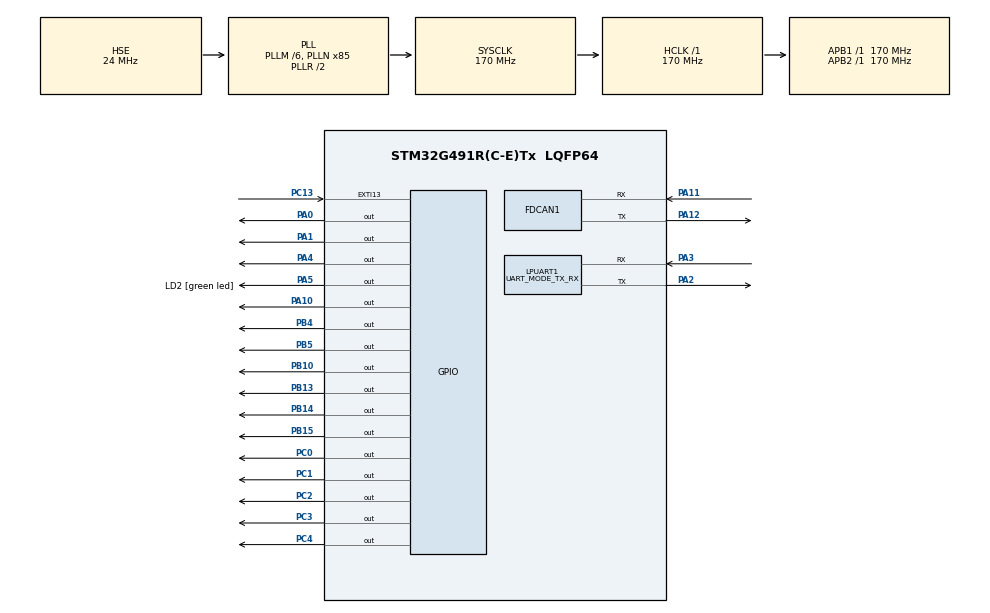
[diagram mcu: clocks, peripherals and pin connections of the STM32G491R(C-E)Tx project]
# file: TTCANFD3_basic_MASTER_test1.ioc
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Dma.LPUART1_TX.0.Direction=DMA_MEMORY_TO_PERIPH
Dma.LPUART1_TX.0.EventEnable=DISABLE
Dma.LPUART1_TX.0.Instance=DMA1_Channel1
Dma.LPUART1_TX.0.MemDataAlignment=DMA_MDATAALIGN_BYTE
Dma.LPUART1_TX.0.MemInc=DMA_MINC_ENABLE
Dma.LPUART1_TX.0.Mode=DMA_NORMAL
Dma.LPUART1_TX.0.PeriphDataAlignment=DMA_PDATAALIGN_BYTE
Dma.LPUART1_TX.0.PeriphInc=DMA_PINC_DISABLE
Dma.LPUART1_TX.0.Polarity=HAL_DMAMUX_REQ_GEN_RISING
Dma.LPUART1_TX.0.Priority=DMA_PRIORITY_VERY_HIGH
Dma.LPUART1_TX.0.RequestNumber=1
Dma.LPUART1_TX.0.SignalID=NONE
Dma.LPUART1_TX.0.SyncEnable=DISABLE
Dma.LPUART1_TX.0.SyncPolarity=HAL_DMAMUX_SYNC_NO_EVENT
Dma.LPUART1_TX.0.SyncRequestNumber=1
Dma.LPUART1_TX.0.SyncSignalID=NONE
Dma.Request0=LPUART1_TX
FDCAN1.AutoRetransmission=DISABLE
FDCAN1.CalculateBaudRateNominal=500000
FDCAN1.CalculateTimeBitNominal=2000
FDCAN1.CalculateTimeQuantumNominal=100.0
FDCAN1.DataPrescaler=5
FDCAN1.DataSyncJumpWidth=8
FDCAN1.DataTimeSeg1=12
FDCAN1.DataTimeSeg2=4
FDCAN1.FrameFormat=FDCAN_FRAME_FD_BRS
FDCAN1.NominalPrescaler=17
FDCAN1.NominalSyncJumpWidth=8
FDCAN1.NominalTimeSeg1=15
FDCAN1.NominalTimeSeg2=4
FDCAN1.ProtocolException=ENABLE
FDCAN1.StdFiltersNbr=1
FDCAN1.TransmitPause=ENABLE
LPUART1.Mode=UART_MODE_TX_RX
Mcu.Family=STM32G4
Mcu.Name=STM32G491R(C-E)Tx
Mcu.Package=LQFP64
NVIC.DMA1_Channel1_IRQn=true\:0\:0\:false\:false\:true\:false\:true\:true
NVIC.EXTI15_10_IRQn=true\:0\:1\:false\:false\:true\:true\:true\:true
NVIC.FDCAN1_IT0_IRQn=true\:0\:1\:false\:false\:true\:true\:true\:true
NVIC.FDCAN1_IT1_IRQn=true\:0\:1\:false\:false\:true\:true\:true\:true
NVIC.LPUART1_IRQn=true\:0\:0\:false\:false\:true\:true\:true\:true
NVIC.PriorityGroup=NVIC_PRIORITYGROUP_3
NVIC.TIM1_BRK_TIM15_IRQn=true\:1\:0\:true\:false\:true\:true\:true\:true
NVIC.TIM1_CC_IRQn=true\:0\:1\:true\:false\:true\:true\:true\:true
NVIC.TIM1_TRG_COM_TIM17_IRQn=true\:1\:0\:true\:false\:true\:true\:true\:true
NVIC.TIM1_UP_TIM16_IRQn=true\:1\:0\:true\:false\:true\:true\:true\:true
NVIC.TIM3_IRQn=true\:0\:1\:true\:false\:true\:true\:true\:true
NVIC.TIM4_IRQn=true\:0\:1\:true\:false\:true\:true\:true\:true
PA0.Signal=GPIO_Output
PA1.Signal=GPIO_Output
PA10.Signal=GPIO_Output
PA11.GPIO_Speed=GPIO_SPEED_FREQ_VERY_HIGH
PA11.Mode=FDCAN_Activate
PA11.Signal=FDCAN1_RX
PA12.GPIO_Speed=GPIO_SPEED_FREQ_VERY_HIGH
PA12.Mode=FDCAN_Activate
PA12.Signal=FDCAN1_TX
PA13.GPIO_Label=T_SWDIO
PA13.Mode=Trace_Asynchronous_SW
PA13.Signal=SYS_JTMS-SWDIO
PA14.GPIO_Label=T_SWCLK
PA14.Mode=Trace_Asynchronous_SW
PA14.Signal=SYS_JTCK-SWCLK
PA2.GPIO_Mode=GPIO_MODE_AF_PP
PA2.GPIO_PuPd=GPIO_NOPULL
PA2.GPIO_Speed=GPIO_SPEED_FREQ_VERY_HIGH
PA2.Mode=Asynchronous
PA2.Signal=LPUART1_TX
PA3.GPIO_Mode=GPIO_MODE_AF_PP
PA3.GPIO_PuPd=GPIO_NOPULL
PA3.GPIO_Speed=GPIO_SPEED_FREQ_VERY_HIGH
PA3.Mode=Asynchronous
PA3.Signal=LPUART1_RX
PA4.Signal=GPIO_Output
PA5.GPIO_Label=LD2 [green led]
PA5.Signal=GPIO_Output
PB10.Signal=GPIO_Output
PB13.Signal=GPIO_Output
PB14.Signal=GPIO_Output
PB15.Signal=GPIO_Output
PB3.GPIO_Label=T_SWO
PB3.Mode=Trace_Asynchronous_SW
PB3.Signal=SYS_JTDO-SWO
PB4.Signal=GPIO_Output
PB5.Signal=GPIO_Output
PC0.Signal=GPIO_Output
PC1.Signal=GPIO_Output
PC13.Signal=GPXTI13
PC14-OSC32_IN.GPIO_Label=RCC_OSC32_IN
PC14-OSC32_IN.Mode=LSE-External-Oscillator
PC14-OSC32_IN.Signal=RCC_OSC32_IN
PC15-OSC32_OUT.GPIO_Label=RCC_OSC32_OUT
PC15-OSC32_OUT.Mode=LSE-External-Oscillator
PC15-OSC32_OUT.Signal=RCC_OSC32_OUT
PC2.Signal=GPIO_Output
PC3.Signal=GPIO_Output
PC4.Signal=GPIO_Output
PF0-OSC_IN.GPIO_Label=RCC_OSC_IN
PF0-OSC_IN.Mode=HSE-External-Oscillator
PF0-OSC_IN.Signal=RCC_OSC_IN
PF1-OSC_OUT.GPIO_Label=RCC_OSC_OUT
PF1-OSC_OUT.Mode=HSE-External-Oscillator
PF1-OSC_OUT.Signal=RCC_OSC_OUT
ProjectManager.HeapSize=0x600
ProjectManager.StackSize=0x600
ProjectManager.TargetToolchain=STM32CubeIDE
RCC.ADC12Freq_Value=170000000
RCC.ADC345Freq_Value=170000000
RCC.AHBFreq_Value=170000000
RCC.APB1Freq_Value=170000000
RCC.APB1TimFreq_Value=170000000
RCC.APB2Freq_Value=170000000
RCC.APB2TimFreq_Value=170000000
RCC.CortexFreq_Value=170000000
RCC.EXTERNAL_CLOCK_VALUE=12288000
RCC.HCLKFreq_Value=170000000
RCC.HSE_VALUE=24000000
RCC.HSI48_VALUE=48000000
RCC.HSI_VALUE=16000000
RCC.LPUART1CLockSelection=RCC_LPUART1CLKSOURCE_HSI
RCC.PLLM=RCC_PLLM_DIV6
RCC.PLLN=85
RCC.PLLSourceVirtual=RCC_PLLSOURCE_HSE
RCC.RTCClockSelection=RCC_RTCCLKSOURCE_LSE
RCC.SYSCLKFreq_VALUE=170000000
RCC.SYSCLKSource=RCC_SYSCLKSOURCE_PLLCLK
RCC.USBFreq_Value=48000000
RCC.VCOOutputFreq_Value=340000000
TIM1.AutoReloadPreload=TIM_AUTORELOAD_PRELOAD_DISABLE
TIM1.Channel-Output\ Compare1\ No\ Output=TIM_CHANNEL_1
TIM1.Channel-Output\ Compare2\ No\ Output=TIM_CHANNEL_2
TIM1.Channel-Output\ Compare3\ No\ Output=TIM_CHANNEL_3
TIM1.Channel-Output\ Compare4\ No\ Output=TIM_CHANNEL_4
TIM1.ClockDivision=TIM_CLOCKDIVISION_DIV1
TIM1.OC1Preload=DISABLE
TIM1.OC2Preload=DISABLE
TIM1.OC3Preload-Output\ Compare3\ No\ Output=DISABLE
TIM1.OC4Preload=DISABLE
TIM1.OCMode_1=TIM_OCMODE_TOGGLE
TIM1.OCMode_2=TIM_OCMODE_TOGGLE
TIM1.OCMode_3=TIM_OCMODE_TOGGLE
TIM1.OCMode_4=TIM_OCMODE_TOGGLE
TIM1.PeriodNoDither=9999
TIM1.Prescaler=170-1
TIM2.Prescaler=170-1
TIM3.Prescaler=170-1
TIM4.PeriodNoDither=150-1
TIM4.Prescaler=170-1
VP_SYS_VS_DBSignals.Mode=DisableDeadBatterySignals
VP_TIM1_VS_ClockSourceINT.Mode=Internal
VP_TIM1_VS_no_output1.Mode=Output Compare1 No Output
VP_TIM1_VS_no_output2.Mode=Output Compare2 No Output
VP_TIM1_VS_no_output3.Mode=Output Compare3 No Output
VP_TIM1_VS_no_output4.Mode=Output Compare4 No Output
VP_TIM2_VS_ClockSourceINT.Mode=Internal
VP_TIM3_VS_ClockSourceINT.Mode=Internal
VP_TIM4_VS_ClockSourceINT.Mode=Internal
board=NUCLEO-G491RE

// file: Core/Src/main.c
/* USER CODE BEGIN Header */
/**
  ******************************************************************************
  * @file           : main.c
  * @brief          : Main program body
  ******************************************************************************
  * @attention
  *
  * Copyright (c) 2026 STMicroelectronics.
  * All rights reserved.
  *
  * This software is licensed under terms that can be found in the LICENSE file
  * in the root directory of this software component.
  * If no LICENSE file comes with this software, it is provided AS-IS.
  *
  ******************************************************************************
  */
/* USER CODE END Header */
#include "main.h"

/* USER CODE BEGIN Includes */
#include "Main_Funcs.h"
/* USER CODE END Includes */

FDCAN_HandleTypeDef hfdcan1;

UART_HandleTypeDef hlpuart1;
DMA_HandleTypeDef hdma_lpuart1_tx;

TIM_HandleTypeDef htim1;
TIM_HandleTypeDef htim2;
TIM_HandleTypeDef htim3;
TIM_HandleTypeDef htim4;

void SystemClock_Config(void);
static void MX_GPIO_Init(void);
static void MX_DMA_Init(void);
static void MX_FDCAN1_Init(void);
static void MX_TIM1_Init(void);
static void MX_TIM2_Init(void);
static void MX_LPUART1_UART_Init(void);
static void MX_TIM3_Init(void);
static void MX_TIM4_Init(void);

int main(void)
{

  /* MCU Configuration--------------------------------------------------------*/

  /* Reset of all peripherals, Initializes the Flash interface and the Systick. */
  HAL_Init();

  /* Configure the system clock */
  SystemClock_Config();

  /* Initialize all configured peripherals */
  MX_GPIO_Init();
  MX_DMA_Init();
  MX_FDCAN1_Init();
  MX_TIM1_Init();
  MX_TIM2_Init();
  MX_LPUART1_UART_Init();
  MX_TIM3_Init();
  MX_TIM4_Init();
  /* USER CODE BEGIN 2 */
  MainInit();
  /* USER CODE END 2 */

  /* Infinite loop */
  /* USER CODE BEGIN WHILE */
  while (1)
  {
	 MainLoop();

    /* USER CODE END WHILE */

  }
}

void SystemClock_Config(void)
{
  RCC_OscInitTypeDef RCC_OscInitStruct = {0};
  RCC_ClkInitTypeDef RCC_ClkInitStruct = {0};

  /** Configure the main internal regulator output voltage
  */
  HAL_PWREx_ControlVoltageScaling(PWR_REGULATOR_VOLTAGE_SCALE1_BOOST);

  /** Initializes the RCC Oscillators according to the specified parameters
  * in the RCC_OscInitTypeDef structure.
  */
  RCC_OscInitStruct.OscillatorType = RCC_OSCILLATORTYPE_HSI|RCC_OSCILLATORTYPE_HSE;
  RCC_OscInitStruct.HSEState = RCC_HSE_ON;
  RCC_OscInitStruct.HSIState = RCC_HSI_ON;
  RCC_OscInitStruct.HSICalibrationValue = RCC_HSICALIBRATION_DEFAULT;
  RCC_OscInitStruct.PLL.PLLState = RCC_PLL_ON;
  RCC_OscInitStruct.PLL.PLLSource = RCC_PLLSOURCE_HSE;
  RCC_OscInitStruct.PLL.PLLM = RCC_PLLM_DIV6;
  RCC_OscInitStruct.PLL.PLLN = 85;
  RCC_OscInitStruct.PLL.PLLP = RCC_PLLP_DIV2;
  RCC_OscInitStruct.PLL.PLLQ = RCC_PLLQ_DIV2;
  RCC_OscInitStruct.PLL.PLLR = RCC_PLLR_DIV2;
  if (HAL_RCC_OscConfig(&RCC_OscInitStruct) != HAL_OK)
  {
    Error_Handler();
  }

  /** Initializes the CPU, AHB and APB buses clocks
  */
  RCC_ClkInitStruct.ClockType = RCC_CLOCKTYPE_HCLK|RCC_CLOCKTYPE_SYSCLK
                              |RCC_CLOCKTYPE_PCLK1|RCC_CLOCKTYPE_PCLK2;
  RCC_ClkInitStruct.SYSCLKSource = RCC_SYSCLKSOURCE_PLLCLK;
  RCC_ClkInitStruct.AHBCLKDivider = RCC_SYSCLK_DIV1;
  RCC_ClkInitStruct.APB1CLKDivider = RCC_HCLK_DIV1;
  RCC_ClkInitStruct.APB2CLKDivider = RCC_HCLK_DIV1;

  if (HAL_RCC_ClockConfig(&RCC_ClkInitStruct, FLASH_LATENCY_4) != HAL_OK)
  {
    Error_Handler();
  }
}

static void MX_FDCAN1_Init(void)
{

  hfdcan1.Instance = FDCAN1;
  hfdcan1.Init.ClockDivider = FDCAN_CLOCK_DIV1;
  hfdcan1.Init.FrameFormat = FDCAN_FRAME_FD_BRS;
  hfdcan1.Init.Mode = FDCAN_MODE_NORMAL;
  hfdcan1.Init.AutoRetransmission = DISABLE;
  hfdcan1.Init.TransmitPause = ENABLE;
  hfdcan1.Init.ProtocolException = ENABLE;
  hfdcan1.Init.NominalPrescaler = 17;
  hfdcan1.Init.NominalSyncJumpWidth = 8;
  hfdcan1.Init.NominalTimeSeg1 = 15;
  hfdcan1.Init.NominalTimeSeg2 = 4;
  hfdcan1.Init.DataPrescaler = 5;
  hfdcan1.Init.DataSyncJumpWidth = 8;
  hfdcan1.Init.DataTimeSeg1 = 12;
  hfdcan1.Init.DataTimeSeg2 = 4;
  hfdcan1.Init.StdFiltersNbr = 1;
  hfdcan1.Init.ExtFiltersNbr = 0;
  hfdcan1.Init.TxFifoQueueMode = FDCAN_TX_FIFO_OPERATION;
  if (HAL_FDCAN_Init(&hfdcan1) != HAL_OK)
  {
    Error_Handler();
  }
  /* USER CODE BEGIN FDCAN1_Init 2 */
  FDCAN_FilterTypeDef canfdfilter;

  canfdfilter.IdType 		= FDCAN_STANDARD_ID;
  canfdfilter.FilterIndex 	= 0;
  canfdfilter.FilterType	= FDCAN_FILTER_RANGE;
  canfdfilter.FilterConfig 	= FDCAN_FILTER_TO_RXFIFO0;
  canfdfilter.FilterID1	    = 0x000;
  canfdfilter.FilterID2		= 0x7FF;

  if (HAL_FDCAN_ConfigFilter(&hfdcan1, &canfdfilter) != HAL_OK)
  {
    Error_Handler();
  }
  /* USER CODE END FDCAN1_Init 2 */

}

static void MX_LPUART1_UART_Init(void)
{

  hlpuart1.Instance = LPUART1;
  hlpuart1.Init.BaudRate = 209700;
  hlpuart1.Init.WordLength = UART_WORDLENGTH_8B;
  hlpuart1.Init.StopBits = UART_STOPBITS_1;
  hlpuart1.Init.Parity = UART_PARITY_NONE;
  hlpuart1.Init.Mode = UART_MODE_TX_RX;
  hlpuart1.Init.HwFlowCtl = UART_HWCONTROL_NONE;
  hlpuart1.Init.OneBitSampling = UART_ONE_BIT_SAMPLE_DISABLE;
  hlpuart1.Init.ClockPrescaler = UART_PRESCALER_DIV1;
  hlpuart1.AdvancedInit.AdvFeatureInit = UART_ADVFEATURE_NO_INIT;
  if (HAL_UART_Init(&hlpuart1) != HAL_OK)
  {
    Error_Handler();
  }
  if (HAL_UARTEx_SetTxFifoThreshold(&hlpuart1, UART_TXFIFO_THRESHOLD_1_8) != HAL_OK)
  {
    Error_Handler();
  }
  if (HAL_UARTEx_SetRxFifoThreshold(&hlpuart1, UART_RXFIFO_THRESHOLD_1_8) != HAL_OK)
  {
    Error_Handler();
  }
  if (HAL_UARTEx_DisableFifoMode(&hlpuart1) != HAL_OK)
  {
    Error_Handler();
  }

}

static void MX_TIM1_Init(void)
{

  TIM_ClockConfigTypeDef sClockSourceConfig = {0};
  TIM_MasterConfigTypeDef sMasterConfig = {0};
  TIM_OC_InitTypeDef sConfigOC = {0};
  TIM_BreakDeadTimeConfigTypeDef sBreakDeadTimeConfig = {0};

  htim1.Instance = TIM1;
  htim1.Init.Prescaler = 170-1;
  htim1.Init.CounterMode = TIM_COUNTERMODE_UP;
  htim1.Init.Period = 9999;
  htim1.Init.ClockDivision = TIM_CLOCKDIVISION_DIV1;
  htim1.Init.RepetitionCounter = 0;
  htim1.Init.AutoReloadPreload = TIM_AUTORELOAD_PRELOAD_DISABLE;
  if (HAL_TIM_Base_Init(&htim1) != HAL_OK)
  {
    Error_Handler();
  }
  sClockSourceConfig.ClockSource = TIM_CLOCKSOURCE_INTERNAL;
  if (HAL_TIM_ConfigClockSource(&htim1, &sClockSourceConfig) != HAL_OK)
  {
    Error_Handler();
  }
  if (HAL_TIM_OC_Init(&htim1) != HAL_OK)
  {
    Error_Handler();
  }
  sMasterConfig.MasterOutputTrigger = TIM_TRGO_RESET;
  sMasterConfig.MasterOutputTrigger2 = TIM_TRGO2_RESET;
  sMasterConfig.MasterSlaveMode = TIM_MASTERSLAVEMODE_DISABLE;
  if (HAL_TIMEx_MasterConfigSynchronization(&htim1, &sMasterConfig) != HAL_OK)
  {
    Error_Handler();
  }
  sConfigOC.OCMode = TIM_OCMODE_TOGGLE;
  sConfigOC.Pulse = 0;
  sConfigOC.OCPolarity = TIM_OCPOLARITY_HIGH;
  sConfigOC.OCNPolarity = TIM_OCNPOLARITY_HIGH;
  sConfigOC.OCFastMode = TIM_OCFAST_DISABLE;
  sConfigOC.OCIdleState = TIM_OCIDLESTATE_RESET;
  sConfigOC.OCNIdleState = TIM_OCNIDLESTATE_RESET;
  if (HAL_TIM_OC_ConfigChannel(&htim1, &sConfigOC, TIM_CHANNEL_1) != HAL_OK)
  {
    Error_Handler();
  }
  if (HAL_TIM_OC_ConfigChannel(&htim1, &sConfigOC, TIM_CHANNEL_2) != HAL_OK)
  {
    Error_Handler();
  }
  if (HAL_TIM_OC_ConfigChannel(&htim1, &sConfigOC, TIM_CHANNEL_3) != HAL_OK)
  {
    Error_Handler();
  }
  if (HAL_TIM_OC_ConfigChannel(&htim1, &sConfigOC, TIM_CHANNEL_4) != HAL_OK)
  {
    Error_Handler();
  }
  sBreakDeadTimeConfig.OffStateRunMode = TIM_OSSR_DISABLE;
  sBreakDeadTimeConfig.OffStateIDLEMode = TIM_OSSI_DISABLE;
  sBreakDeadTimeConfig.LockLevel = TIM_LOCKLEVEL_OFF;
  sBreakDeadTimeConfig.DeadTime = 0;
  sBreakDeadTimeConfig.BreakState = TIM_BREAK_DISABLE;
  sBreakDeadTimeConfig.BreakPolarity = TIM_BREAKPOLARITY_HIGH;
  sBreakDeadTimeConfig.BreakFilter = 0;
  sBreakDeadTimeConfig.BreakAFMode = TIM_BREAK_AFMODE_INPUT;
  sBreakDeadTimeConfig.Break2State = TIM_BREAK2_DISABLE;
  sBreakDeadTimeConfig.Break2Polarity = TIM_BREAK2POLARITY_HIGH;
  sBreakDeadTimeConfig.Break2Filter = 0;
  sBreakDeadTimeConfig.Break2AFMode = TIM_BREAK_AFMODE_INPUT;
  sBreakDeadTimeConfig.AutomaticOutput = TIM_AUTOMATICOUTPUT_DISABLE;
  if (HAL_TIMEx_ConfigBreakDeadTime(&htim1, &sBreakDeadTimeConfig) != HAL_OK)
  {
    Error_Handler();
  }

}

static void MX_TIM2_Init(void)
{

  TIM_ClockConfigTypeDef sClockSourceConfig = {0};
  TIM_MasterConfigTypeDef sMasterConfig = {0};

  htim2.Instance = TIM2;
  htim2.Init.Prescaler = 170-1;
  htim2.Init.CounterMode = TIM_COUNTERMODE_UP;
  htim2.Init.Period = 4294967295;
  htim2.Init.ClockDivision = TIM_CLOCKDIVISION_DIV1;
  htim2.Init.AutoReloadPreload = TIM_AUTORELOAD_PRELOAD_DISABLE;
  if (HAL_TIM_Base_Init(&htim2) != HAL_OK)
  {
    Error_Handler();
  }
  sClockSourceConfig.ClockSource = TIM_CLOCKSOURCE_INTERNAL;
  if (HAL_TIM_ConfigClockSource(&htim2, &sClockSourceConfig) != HAL_OK)
  {
    Error_Handler();
  }
  sMasterConfig.MasterOutputTrigger = TIM_TRGO_RESET;
  sMasterConfig.MasterSlaveMode = TIM_MASTERSLAVEMODE_DISABLE;
  if (HAL_TIMEx_MasterConfigSynchronization(&htim2, &sMasterConfig) != HAL_OK)
  {
    Error_Handler();
  }

}

static void MX_TIM3_Init(void)
{

  TIM_ClockConfigTypeDef sClockSourceConfig = {0};
  TIM_MasterConfigTypeDef sMasterConfig = {0};

  htim3.Instance = TIM3;
  htim3.Init.Prescaler = 170-1;
  htim3.Init.CounterMode = TIM_COUNTERMODE_UP;
  htim3.Init.Period = 65535;
  htim3.Init.ClockDivision = TIM_CLOCKDIVISION_DIV1;
  htim3.Init.AutoReloadPreload = TIM_AUTORELOAD_PRELOAD_DISABLE;
  if (HAL_TIM_Base_Init(&htim3) != HAL_OK)
  {
    Error_Handler();
  }
  sClockSourceConfig.ClockSource = TIM_CLOCKSOURCE_INTERNAL;
  if (HAL_TIM_ConfigClockSource(&htim3, &sClockSourceConfig) != HAL_OK)
  {
    Error_Handler();
  }
  sMasterConfig.MasterOutputTrigger = TIM_TRGO_RESET;
  sMasterConfig.MasterSlaveMode = TIM_MASTERSLAVEMODE_DISABLE;
  if (HAL_TIMEx_MasterConfigSynchronization(&htim3, &sMasterConfig) != HAL_OK)
  {
    Error_Handler();
  }

}

static void MX_TIM4_Init(void)
{

  TIM_ClockConfigTypeDef sClockSourceConfig = {0};
  TIM_MasterConfigTypeDef sMasterConfig = {0};

  htim4.Instance = TIM4;
  htim4.Init.Prescaler = 170-1;
  htim4.Init.CounterMode = TIM_COUNTERMODE_UP;
  htim4.Init.Period = 149;
  htim4.Init.ClockDivision = TIM_CLOCKDIVISION_DIV1;
  htim4.Init.AutoReloadPreload = TIM_AUTORELOAD_PRELOAD_DISABLE;
  if (HAL_TIM_Base_Init(&htim4) != HAL_OK)
  {
    Error_Handler();
  }
  sClockSourceConfig.ClockSource = TIM_CLOCKSOURCE_INTERNAL;
  if (HAL_TIM_ConfigClockSource(&htim4, &sClockSourceConfig) != HAL_OK)
  {
    Error_Handler();
  }
  sMasterConfig.MasterOutputTrigger = TIM_TRGO_RESET;
  sMasterConfig.MasterSlaveMode = TIM_MASTERSLAVEMODE_DISABLE;
  if (HAL_TIMEx_MasterConfigSynchronization(&htim4, &sMasterConfig) != HAL_OK)
  {
    Error_Handler();
  }

}

static void MX_DMA_Init(void)
{

  /* DMA controller clock enable */
  __HAL_RCC_DMAMUX1_CLK_ENABLE();
  __HAL_RCC_DMA1_CLK_ENABLE();

  /* DMA interrupt init */
  /* DMA1_Channel1_IRQn interrupt configuration */
  HAL_NVIC_SetPriority(DMA1_Channel1_IRQn, 0, 0);
  HAL_NVIC_EnableIRQ(DMA1_Channel1_IRQn);

}

static void MX_GPIO_Init(void)
{
  GPIO_InitTypeDef GPIO_InitStruct = {0};

  /* GPIO Ports Clock Enable */
  __HAL_RCC_GPIOC_CLK_ENABLE();
  __HAL_RCC_GPIOF_CLK_ENABLE();
  __HAL_RCC_GPIOA_CLK_ENABLE();
  __HAL_RCC_GPIOB_CLK_ENABLE();

  /*Configure GPIO pin Output Level */
  HAL_GPIO_WritePin(GPIOC, GPIO_PIN_0|GPIO_PIN_1|GPIO_PIN_2|GPIO_PIN_3
                          |GPIO_PIN_4, GPIO_PIN_RESET);

  /*Configure GPIO pin Output Level */
  HAL_GPIO_WritePin(GPIOA, GPIO_PIN_0|GPIO_PIN_1|GPIO_PIN_4|LD2_Pin
                          |GPIO_PIN_10, GPIO_PIN_RESET);

  /*Configure GPIO pin Output Level */
  HAL_GPIO_WritePin(GPIOB, GPIO_PIN_10|GPIO_PIN_13|GPIO_PIN_14|GPIO_PIN_15
                          |GPIO_PIN_4|GPIO_PIN_5, GPIO_PIN_RESET);

  /*Configure GPIO pin : PC13 */
  GPIO_InitStruct.Pin = GPIO_PIN_13;
  GPIO_InitStruct.Mode = GPIO_MODE_IT_RISING;
  GPIO_InitStruct.Pull = GPIO_NOPULL;
  HAL_GPIO_Init(GPIOC, &GPIO_InitStruct);

  /*Configure GPIO pins : PC0 PC1 PC2 PC3
                           PC4 */
  GPIO_InitStruct.Pin = GPIO_PIN_0|GPIO_PIN_1|GPIO_PIN_2|GPIO_PIN_3
                          |GPIO_PIN_4;
  GPIO_InitStruct.Mode = GPIO_MODE_OUTPUT_PP;
  GPIO_InitStruct.Pull = GPIO_NOPULL;
  GPIO_InitStruct.Speed = GPIO_SPEED_FREQ_LOW;
  HAL_GPIO_Init(GPIOC, &GPIO_InitStruct);

  /*Configure GPIO pins : PA0 PA1 PA4 LD2_Pin
                           PA10 */
  GPIO_InitStruct.Pin = GPIO_PIN_0|GPIO_PIN_1|GPIO_PIN_4|LD2_Pin
                          |GPIO_PIN_10;
  GPIO_InitStruct.Mode = GPIO_MODE_OUTPUT_PP;
  GPIO_InitStruct.Pull = GPIO_NOPULL;
  GPIO_InitStruct.Speed = GPIO_SPEED_FREQ_LOW;
  HAL_GPIO_Init(GPIOA, &GPIO_InitStruct);

  /*Configure GPIO pins : PB10 PB13 PB14 PB15
                           PB4 PB5 */
  GPIO_InitStruct.Pin = GPIO_PIN_10|GPIO_PIN_13|GPIO_PIN_14|GPIO_PIN_15
                          |GPIO_PIN_4|GPIO_PIN_5;
  GPIO_InitStruct.Mode = GPIO_MODE_OUTPUT_PP;
  GPIO_InitStruct.Pull = GPIO_NOPULL;
  GPIO_InitStruct.Speed = GPIO_SPEED_FREQ_LOW;
  HAL_GPIO_Init(GPIOB, &GPIO_InitStruct);

  /* EXTI interrupt init*/
  HAL_NVIC_SetPriority(EXTI15_10_IRQn, 0, 1);
  HAL_NVIC_EnableIRQ(EXTI15_10_IRQn);

}

void Error_Handler(void)
{
  __disable_irq();
  while (1)
  {
  }
}
